# CH32F103xx register map
Vendor: WCH Ltd.; File version: 1.0
Registers are 32-bit, read-write, reset 0x0 unless marked. A register's access mark holds for its fields unless they carry their own. Offsets are from the block's base; [hi:lo] are bit positions; lines under a group give offsets from that group; {n}, {i} and the like mark numbered series.

## ADC_TKEY_F — Analog to digital converter_Touch key_F
Base 0x40012400
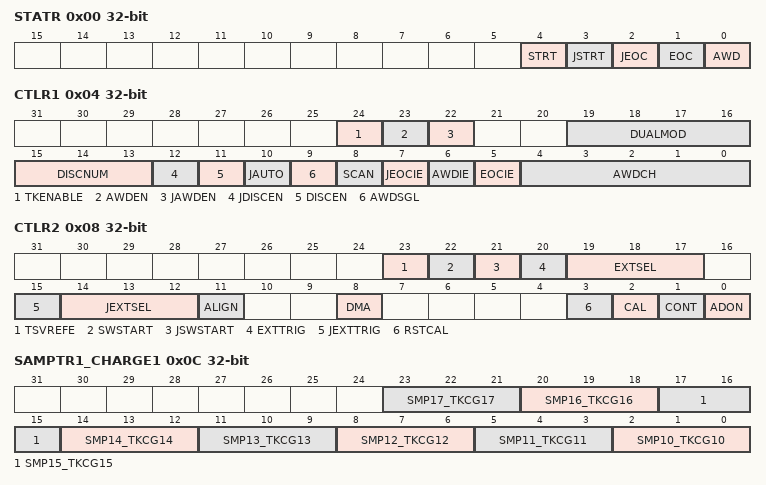
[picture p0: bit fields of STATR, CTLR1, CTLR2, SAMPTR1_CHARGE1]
0x00 STATR — status register
  [4] STRT — Regular channel start flag
  [3] JSTRT — Injected channel start flag
  [2] JEOC — Injected channel end of conversion
  [1] EOC — Regular channel end of conversion
  [0] AWD — Analog watchdog flag
0x04 CTLR1 — control register 1
  [24] TKENABLE — Touch key enable, including TKEY_F and TKEY_V
  [23] AWDEN — Analog watchdog enable on regular channels
  [22] JAWDEN — Analog watchdog enable on injected channels
  [19:16] DUALMOD — Dual mode selection
  [15:13] DISCNUM — Discontinuous mode channel count
  [12] JDISCEN — Discontinuous mode on injected channels
  [11] DISCEN — Discontinuous mode on regular channels
  [10] JAUTO — Automatic injected group conversion
  [9] AWDSGL — Enable the watchdog on a single channel in scan mode
  [8] SCAN — Scan mode
  [7] JEOCIE — Interrupt enable for injected channels
  [6] AWDIE — Analog watchdog interrupt enable
  [5] EOCIE — Interrupt enable for EOC
  [4:0] AWDCH — Analog watchdog channel select bits
0x08 CTLR2 — control register 2
  [23] TSVREFE — Temperature sensor and VREFINT enable
  [22] SWSTART — Start conversion of regular channels
  [21] JSWSTART — Start conversion of injected channels
  [20] EXTTRIG — External trigger conversion mode for regular channels
  [19:17] EXTSEL — External event select for regular group
  [15] JEXTTRIG — External trigger conversion mode for injected channels
  [14:12] JEXTSEL — External event select for injected group
  [11] ALIGN — Data alignment
  [8] DMA — Direct memory access mode
  [3] RSTCAL — Reset calibration
  [2] CAL — A/D calibration
  [1] CONT — Continuous conversion
  [0] ADON — A/D converter ON / OFF
0x0C SAMPTR1_CHARGE1 — sample time register 1
  [3n-28:3n-30] SMP{n}_TKCG{n} (n=10..17) — Channel {n} sample time selection
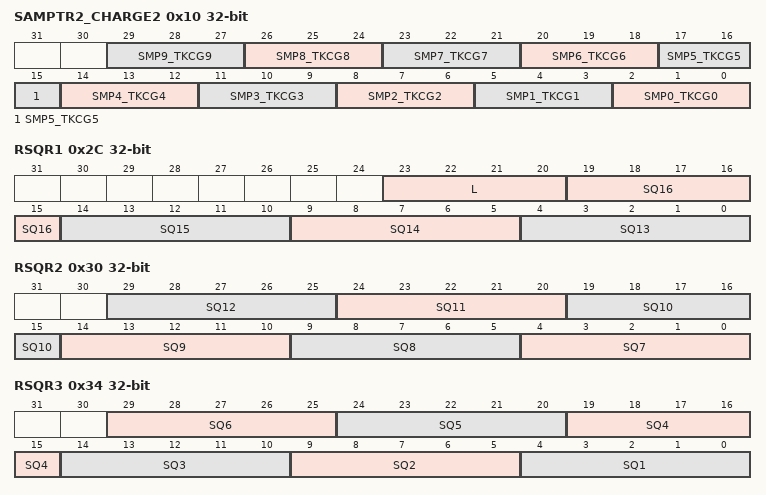
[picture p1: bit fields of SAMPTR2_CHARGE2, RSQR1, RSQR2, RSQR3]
0x10 SAMPTR2_CHARGE2 — sample time register 2
  [3n+2:3n] SMP{n}_TKCG{n} (n=0..9) — Channel {n} sample time selection
{0x10+4i} IOFR{i} (i=1..4) — injected channel data offset register x
  [11:0] JOFFSET{i} — Data offset for injected channel x
0x24 WDHTR — watchdog higher threshold register
  [11:0] HT — Analog watchdog higher threshold
0x28 WDLTR — watchdog lower threshold register
  [11:0] LT — Analog watchdog lower threshold
0x2C RSQR1 — regular sequence register 1
  [23:20] L — Regular channel sequence length
  [5n-61:5n-65] SQ{n} (n=13..16) — {n}th conversion in regular sequence
0x30 RSQR2 — regular sequence register 2
  [5n-31:5n-35] SQ{n} (n=7..12) — {n}th conversion in regular sequence
0x34 RSQR3 — regular sequence register 3
  [29:25] SQ6 — 6th conversion in regular sequence
  [24:20] SQ5 — 5th conversion in regular sequence
  [19:15] SQ4 — 4th conversion in regular sequence
  [14:10] SQ3 — 3rd conversion in regular sequence
  [9:5] SQ2 — 2nd conversion in regular sequence
  [4:0] SQ1 — 1st conversion in regular sequence
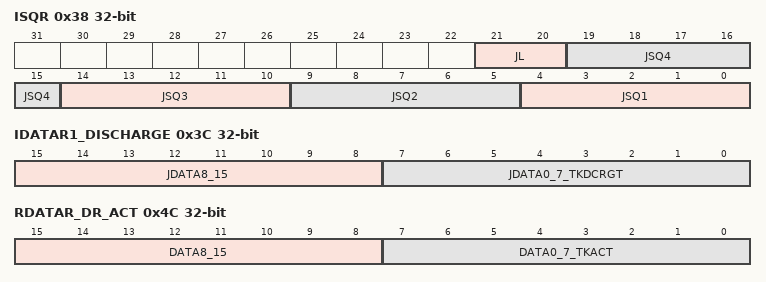
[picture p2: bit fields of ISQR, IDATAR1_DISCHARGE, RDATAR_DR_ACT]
0x38 ISQR — injected sequence register
  [21:20] JL — Injected sequence length
  [19:15] JSQ4 — 4th conversion in injected sequence
  [14:10] JSQ3 — 3rd conversion in injected sequence
  [9:5] JSQ2 — 2nd conversion in injected sequence
  [4:0] JSQ1 — 1st conversion in injected sequence
0x3C IDATAR1_DISCHARGE ro — injected data register x_Discharge time register
  [15:8] JDATA8_15 — Injected
  [7:0] JDATA0_7_TKDCRGT — Injected_Touch key discharge time
{0x38+4i} IDATAR{i} ro (i=2..4) — injected data register x
  [15:0] JDATA — Injected data
0x4C RDATAR_DR_ACT read-only_write-only — regular data register_start and discharge time register
  [15:8] DATA8_15 — Regular data
  [7:0] DATA0_7_TKACT — Regular data_Touch key start and discharge time register

## DAC1 — Digital to analog converter
Base 0x40007400
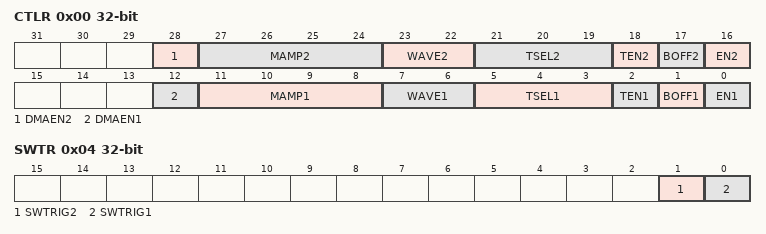
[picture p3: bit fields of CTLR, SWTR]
0x00 CTLR — Control register (DAC_CTLR)
  [28] DMAEN2 — DAC channel2 DMA enable
  [27:24] MAMP2 — DAC channel2 mask/amplitude selector
  [23:22] WAVE2 — DAC channel2 noise/triangle wave generation enable
  [21:19] TSEL2 — DAC channel2 trigger selection
  [18] TEN2 — DAC channel2 trigger enable
  [17] BOFF2 — DAC channel2 output buffer disable
  [16] EN2 — DAC channel2 enable
  [12] DMAEN1 — DAC channel1 DMA enable
  [11:8] MAMP1 — DAC channel1 mask/amplitude selector
  [7:6] WAVE1 — DAC channel1 noise/triangle wave generation enable
  [5:3] TSEL1 — DAC channel1 trigger selection
  [2] TEN1 — DAC channel1 trigger enable
  [1] BOFF1 — DAC channel1 output buffer disable
  [0] EN1 — DAC channel1 enable
0x04 SWTR wo — DAC software trigger register (DAC_SWTR)
  [1] SWTRIG2 — DAC channel2 software trigger
  [0] SWTRIG1 — DAC channel1 software trigger
0x08 R12BDHR1 — DAC channel1 12-bit right-aligned data holding register(DAC_R12BDHR1)
  [11:0] DACC1DHR — DAC channel1 12-bit right-aligned data
0x0C L12BDHR1 — DAC channel1 12-bit left aligned data holding register (DAC_L12BDHR1)
  [15:4] DACC1DHR — DAC channel1 12-bit left-aligned data
0x14 R12BDHR2 — DAC channel2 12-bit right aligned data holding register (DAC_R12BDHR2)
  [11:0] DACC2DHR — DAC channel2 12-bit right-aligned data
0x18 L12BDHR2 — DAC channel2 12-bit left aligned data holding register (DAC_L12BDHR2)
  [15:4] DACC2DHR — DAC channel2 12-bit left-aligned data
0x2C DOR1 ro — DAC channel1 data output register (DAC_DOR1)
  [11:0] DACC1DOR — DAC channel1 data output
0x30 DOR2 ro — DAC channel2 data output register (DAC_DOR2)
  [11:0] DACC2DOR — DAC channel2 data output
